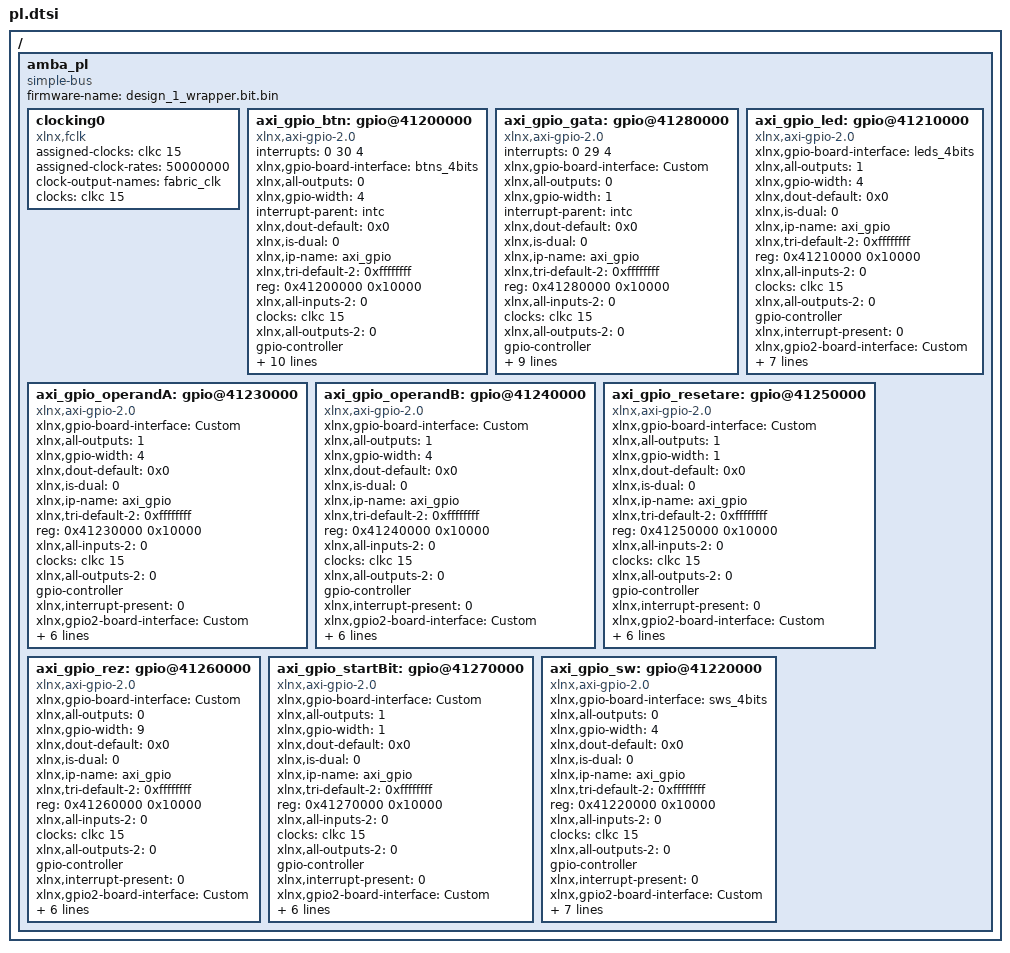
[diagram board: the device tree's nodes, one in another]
/ {
	amba_pl: amba_pl {
		ranges;
		compatible = "simple-bus";
		#address-cells = <1>;
		#size-cells = <1>;
		firmware-name = "design_1_wrapper.bit.bin";
		clocking0: clocking0 {
			compatible = "xlnx,fclk";
			assigned-clocks = <&clkc 15>;
			assigned-clock-rates = <50000000>;
			#clock-cells = <0>;
			clock-output-names = "fabric_clk";
			clocks = <&clkc 15>;
		};
		axi_gpio_btn: gpio@41200000 {
			#interrupt-cells = <2>;
			interrupts = < 0 30 4 >;
			xlnx,gpio-board-interface = "btns_4bits";
			compatible = "xlnx,axi-gpio-2.0" , "xlnx,xps-gpio-1.00.a";
			xlnx,all-outputs = <0>;
			#gpio-cells = <2>;
			xlnx,gpio-width = <4>;
			interrupt-parent = <&intc>;
			xlnx,dout-default = <0x0>;
			xlnx,is-dual = <0>;
			xlnx,ip-name = "axi_gpio";
			xlnx,tri-default-2 = <0xffffffff>;
			reg = <0x41200000 0x10000>;
			xlnx,all-inputs-2 = <0>;
			clocks = <&clkc 15>;
			xlnx,all-outputs-2 = <0>;
			gpio-controller;
			xlnx,interrupt-present = <1>;
			xlnx,gpio2-board-interface = "Custom";
			xlnx,edk-iptype = "PERIPHERAL";
			xlnx,dout-default-2 = <0x0>;
			status = "okay";
			xlnx,gpio2-width = <32>;
			clock-names = "s_axi_aclk";
			xlnx,use-board-flow;
			interrupt-controller;
			interrupt-names = "ip2intc_irpt";
			xlnx,tri-default = <0xffffffff>;
			xlnx,name = "axi_gpio_btn";
			xlnx,all-inputs = <1>;
		};
		axi_gpio_gata: gpio@41280000 {
			#interrupt-cells = <2>;
			interrupts = < 0 29 4 >;
			xlnx,gpio-board-interface = "Custom";
			compatible = "xlnx,axi-gpio-2.0" , "xlnx,xps-gpio-1.00.a";
			xlnx,all-outputs = <0>;
			#gpio-cells = <2>;
			xlnx,gpio-width = <1>;
			interrupt-parent = <&intc>;
			xlnx,dout-default = <0x0>;
			xlnx,is-dual = <0>;
			xlnx,ip-name = "axi_gpio";
			xlnx,tri-default-2 = <0xffffffff>;
			reg = <0x41280000 0x10000>;
			xlnx,all-inputs-2 = <0>;
			clocks = <&clkc 15>;
			xlnx,all-outputs-2 = <0>;
			gpio-controller;
			xlnx,interrupt-present = <1>;
			xlnx,gpio2-board-interface = "Custom";
			xlnx,edk-iptype = "PERIPHERAL";
			xlnx,dout-default-2 = <0x0>;
			status = "okay";
			xlnx,gpio2-width = <32>;
			clock-names = "s_axi_aclk";
			interrupt-controller;
			interrupt-names = "ip2intc_irpt";
			xlnx,tri-default = <0xffffffff>;
			xlnx,name = "axi_gpio_gata";
			xlnx,all-inputs = <1>;
		};
		axi_gpio_led: gpio@41210000 {
			xlnx,gpio-board-interface = "leds_4bits";
			compatible = "xlnx,axi-gpio-2.0" , "xlnx,xps-gpio-1.00.a";
			xlnx,all-outputs = <1>;
			#gpio-cells = <2>;
			xlnx,gpio-width = <4>;
			xlnx,dout-default = <0x0>;
			xlnx,is-dual = <0>;
			xlnx,ip-name = "axi_gpio";
			xlnx,tri-default-2 = <0xffffffff>;
			reg = <0x41210000 0x10000>;
			xlnx,all-inputs-2 = <0>;
			clocks = <&clkc 15>;
			xlnx,all-outputs-2 = <0>;
			gpio-controller;
			xlnx,interrupt-present = <0>;
			xlnx,gpio2-board-interface = "Custom";
			xlnx,edk-iptype = "PERIPHERAL";
			xlnx,dout-default-2 = <0x0>;
			status = "okay";
			xlnx,gpio2-width = <32>;
			clock-names = "s_axi_aclk";
			xlnx,use-board-flow;
			xlnx,tri-default = <0xffffffff>;
			xlnx,name = "axi_gpio_led";
			xlnx,all-inputs = <0>;
		};
		axi_gpio_operandA: gpio@41230000 {
			xlnx,gpio-board-interface = "Custom";
			compatible = "xlnx,axi-gpio-2.0" , "xlnx,xps-gpio-1.00.a";
			xlnx,all-outputs = <1>;
			#gpio-cells = <2>;
			xlnx,gpio-width = <4>;
			xlnx,dout-default = <0x0>;
			xlnx,is-dual = <0>;
			xlnx,ip-name = "axi_gpio";
			xlnx,tri-default-2 = <0xffffffff>;
			reg = <0x41230000 0x10000>;
			xlnx,all-inputs-2 = <0>;
			clocks = <&clkc 15>;
			xlnx,all-outputs-2 = <0>;
			gpio-controller;
			xlnx,interrupt-present = <0>;
			xlnx,gpio2-board-interface = "Custom";
			xlnx,edk-iptype = "PERIPHERAL";
			xlnx,dout-default-2 = <0x0>;
			status = "okay";
			xlnx,gpio2-width = <32>;
			clock-names = "s_axi_aclk";
			xlnx,tri-default = <0xffffffff>;
			xlnx,name = "axi_gpio_operandA";
			xlnx,all-inputs = <0>;
		};
		axi_gpio_operandB: gpio@41240000 {
			xlnx,gpio-board-interface = "Custom";
			compatible = "xlnx,axi-gpio-2.0" , "xlnx,xps-gpio-1.00.a";
			xlnx,all-outputs = <1>;
			#gpio-cells = <2>;
			xlnx,gpio-width = <4>;
			xlnx,dout-default = <0x0>;
			xlnx,is-dual = <0>;
			xlnx,ip-name = "axi_gpio";
			xlnx,tri-default-2 = <0xffffffff>;
			reg = <0x41240000 0x10000>;
			xlnx,all-inputs-2 = <0>;
			clocks = <&clkc 15>;
			xlnx,all-outputs-2 = <0>;
			gpio-controller;
			xlnx,interrupt-present = <0>;
			xlnx,gpio2-board-interface = "Custom";
			xlnx,edk-iptype = "PERIPHERAL";
			xlnx,dout-default-2 = <0x0>;
			status = "okay";
			xlnx,gpio2-width = <32>;
			clock-names = "s_axi_aclk";
			xlnx,tri-default = <0xffffffff>;
			xlnx,name = "axi_gpio_operandB";
			xlnx,all-inputs = <0>;
		};
		axi_gpio_resetare: gpio@41250000 {
			xlnx,gpio-board-interface = "Custom";
			compatible = "xlnx,axi-gpio-2.0" , "xlnx,xps-gpio-1.00.a";
			xlnx,all-outputs = <1>;
			#gpio-cells = <2>;
			xlnx,gpio-width = <1>;
			xlnx,dout-default = <0x0>;
			xlnx,is-dual = <0>;
			xlnx,ip-name = "axi_gpio";
			xlnx,tri-default-2 = <0xffffffff>;
			reg = <0x41250000 0x10000>;
			xlnx,all-inputs-2 = <0>;
			clocks = <&clkc 15>;
			xlnx,all-outputs-2 = <0>;
			gpio-controller;
			xlnx,interrupt-present = <0>;
			xlnx,gpio2-board-interface = "Custom";
			xlnx,edk-iptype = "PERIPHERAL";
			xlnx,dout-default-2 = <0x0>;
			status = "okay";
			xlnx,gpio2-width = <32>;
			clock-names = "s_axi_aclk";
			xlnx,tri-default = <0xffffffff>;
			xlnx,name = "axi_gpio_resetare";
			xlnx,all-inputs = <0>;
		};
		axi_gpio_rez: gpio@41260000 {
			xlnx,gpio-board-interface = "Custom";
			compatible = "xlnx,axi-gpio-2.0" , "xlnx,xps-gpio-1.00.a";
			xlnx,all-outputs = <0>;
			#gpio-cells = <2>;
			xlnx,gpio-width = <9>;
			xlnx,dout-default = <0x0>;
			xlnx,is-dual = <0>;
			xlnx,ip-name = "axi_gpio";
			xlnx,tri-default-2 = <0xffffffff>;
			reg = <0x41260000 0x10000>;
			xlnx,all-inputs-2 = <0>;
			clocks = <&clkc 15>;
			xlnx,all-outputs-2 = <0>;
			gpio-controller;
			xlnx,interrupt-present = <0>;
			xlnx,gpio2-board-interface = "Custom";
			xlnx,edk-iptype = "PERIPHERAL";
			xlnx,dout-default-2 = <0x0>;
			status = "okay";
			xlnx,gpio2-width = <32>;
			clock-names = "s_axi_aclk";
			xlnx,tri-default = <0xffffffff>;
			xlnx,name = "axi_gpio_rez";
			xlnx,all-inputs = <1>;
		};
		axi_gpio_startBit: gpio@41270000 {
			xlnx,gpio-board-interface = "Custom";
			compatible = "xlnx,axi-gpio-2.0" , "xlnx,xps-gpio-1.00.a";
			xlnx,all-outputs = <1>;
			#gpio-cells = <2>;
			xlnx,gpio-width = <1>;
			xlnx,dout-default = <0x0>;
			xlnx,is-dual = <0>;
			xlnx,ip-name = "axi_gpio";
			xlnx,tri-default-2 = <0xffffffff>;
			reg = <0x41270000 0x10000>;
			xlnx,all-inputs-2 = <0>;
			clocks = <&clkc 15>;
			xlnx,all-outputs-2 = <0>;
			gpio-controller;
			xlnx,interrupt-present = <0>;
			xlnx,gpio2-board-interface = "Custom";
			xlnx,edk-iptype = "PERIPHERAL";
			xlnx,dout-default-2 = <0x0>;
			status = "okay";
			xlnx,gpio2-width = <32>;
			clock-names = "s_axi_aclk";
			xlnx,tri-default = <0xffffffff>;
			xlnx,name = "axi_gpio_startBit";
			xlnx,all-inputs = <0>;
		};
		axi_gpio_sw: gpio@41220000 {
			xlnx,gpio-board-interface = "sws_4bits";
			compatible = "xlnx,axi-gpio-2.0" , "xlnx,xps-gpio-1.00.a";
			xlnx,all-outputs = <0>;
			#gpio-cells = <2>;
			xlnx,gpio-width = <4>;
			xlnx,dout-default = <0x0>;
			xlnx,is-dual = <0>;
			xlnx,ip-name = "axi_gpio";
			xlnx,tri-default-2 = <0xffffffff>;
			reg = <0x41220000 0x10000>;
			xlnx,all-inputs-2 = <0>;
			clocks = <&clkc 15>;
			xlnx,all-outputs-2 = <0>;
			gpio-controller;
			xlnx,interrupt-present = <0>;
			xlnx,gpio2-board-interface = "Custom";
			xlnx,edk-iptype = "PERIPHERAL";
			xlnx,dout-default-2 = <0x0>;
			status = "okay";
			xlnx,gpio2-width = <32>;
			clock-names = "s_axi_aclk";
			xlnx,use-board-flow;
			xlnx,tri-default = <0xffffffff>;
			xlnx,name = "axi_gpio_sw";
			xlnx,all-inputs = <1>;
		};
	};
};
